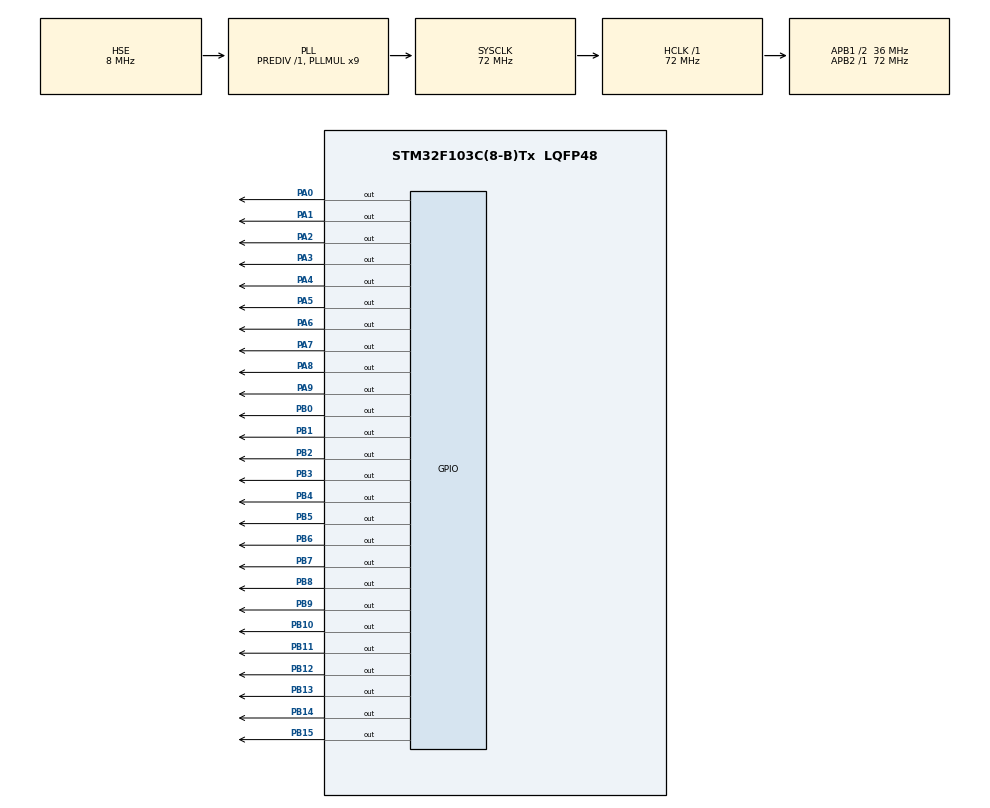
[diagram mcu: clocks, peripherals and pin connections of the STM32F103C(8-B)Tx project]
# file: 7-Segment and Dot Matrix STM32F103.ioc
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FREERTOS.Tasks01=defaultTask,24,128,StartDefaultTask,Default,NULL,Dynamic,NULL,NULL;display,8,256,Dispay01,Default,NULL,Dynamic,NULL,NULL
FREERTOS.configTOTAL_HEAP_SIZE=8096
FREERTOS.configUSE_NEWLIB_REENTRANT=1
Mcu.Family=STM32F1
Mcu.Name=STM32F103C(8-B)Tx
Mcu.Package=LQFP48
NVIC.PriorityGroup=NVIC_PRIORITYGROUP_4
NVIC.TIM3_IRQn=true\:15\:0\:false\:false\:true\:false\:false\:true
NVIC.TimeBase=TIM3_IRQn
NVIC.TimeBaseIP=TIM3
PA0-WKUP.GPIO_PuPd=GPIO_PULLUP
PA0-WKUP.GPIO_Speed=GPIO_SPEED_FREQ_HIGH
PA0-WKUP.PinState=GPIO_PIN_SET
PA0-WKUP.Signal=GPIO_Output
PA1.GPIO_PuPd=GPIO_PULLUP
PA1.GPIO_Speed=GPIO_SPEED_FREQ_HIGH
PA1.PinState=GPIO_PIN_SET
PA1.Signal=GPIO_Output
PA13.Mode=Serial_Wire
PA13.Signal=SYS_JTMS-SWDIO
PA14.Mode=Serial_Wire
PA14.Signal=SYS_JTCK-SWCLK
PA2.GPIO_PuPd=GPIO_PULLUP
PA2.GPIO_Speed=GPIO_SPEED_FREQ_HIGH
PA2.PinState=GPIO_PIN_SET
PA2.Signal=GPIO_Output
PA3.GPIO_PuPd=GPIO_PULLUP
PA3.GPIO_Speed=GPIO_SPEED_FREQ_HIGH
PA3.PinState=GPIO_PIN_SET
PA3.Signal=GPIO_Output
PA4.GPIO_PuPd=GPIO_PULLUP
PA4.GPIO_Speed=GPIO_SPEED_FREQ_HIGH
PA4.PinState=GPIO_PIN_SET
PA4.Signal=GPIO_Output
PA5.GPIO_PuPd=GPIO_PULLUP
PA5.GPIO_Speed=GPIO_SPEED_FREQ_HIGH
PA5.PinState=GPIO_PIN_SET
PA5.Signal=GPIO_Output
PA6.GPIO_PuPd=GPIO_PULLUP
PA6.GPIO_Speed=GPIO_SPEED_FREQ_HIGH
PA6.PinState=GPIO_PIN_SET
PA6.Signal=GPIO_Output
PA7.GPIO_PuPd=GPIO_PULLUP
PA7.GPIO_Speed=GPIO_SPEED_FREQ_HIGH
PA7.PinState=GPIO_PIN_SET
PA7.Signal=GPIO_Output
PA8.GPIO_PuPd=GPIO_PULLUP
PA8.GPIO_Speed=GPIO_SPEED_FREQ_HIGH
PA8.PinState=GPIO_PIN_RESET
PA8.Signal=GPIO_Output
PA9.GPIO_PuPd=GPIO_PULLUP
PA9.GPIO_Speed=GPIO_SPEED_FREQ_HIGH
PA9.PinState=GPIO_PIN_RESET
PA9.Signal=GPIO_Output
PB0.GPIO_ModeDefaultOutputPP=GPIO_MODE_OUTPUT_PP
PB0.GPIO_PuPd=GPIO_PULLUP
PB0.GPIO_Speed=GPIO_SPEED_FREQ_HIGH
PB0.PinState=GPIO_PIN_SET
PB0.Signal=GPIO_Output
PB1.GPIO_ModeDefaultOutputPP=GPIO_MODE_OUTPUT_PP
PB1.GPIO_PuPd=GPIO_PULLUP
PB1.GPIO_Speed=GPIO_SPEED_FREQ_HIGH
PB1.PinState=GPIO_PIN_SET
PB1.Signal=GPIO_Output
PB10.GPIO_ModeDefaultOutputPP=GPIO_MODE_OUTPUT_PP
PB10.GPIO_PuPd=GPIO_PULLUP
PB10.GPIO_Speed=GPIO_SPEED_FREQ_HIGH
PB10.PinState=GPIO_PIN_SET
PB10.Signal=GPIO_Output
PB11.GPIO_ModeDefaultOutputPP=GPIO_MODE_OUTPUT_PP
PB11.GPIO_PuPd=GPIO_PULLUP
PB11.GPIO_Speed=GPIO_SPEED_FREQ_HIGH
PB11.PinState=GPIO_PIN_SET
PB11.Signal=GPIO_Output
PB12.GPIO_ModeDefaultOutputPP=GPIO_MODE_OUTPUT_PP
PB12.GPIO_PuPd=GPIO_PULLUP
PB12.GPIO_Speed=GPIO_SPEED_FREQ_HIGH
PB12.PinState=GPIO_PIN_SET
PB12.Signal=GPIO_Output
PB13.GPIO_ModeDefaultOutputPP=GPIO_MODE_OUTPUT_PP
PB13.GPIO_PuPd=GPIO_PULLUP
PB13.GPIO_Speed=GPIO_SPEED_FREQ_HIGH
PB13.PinState=GPIO_PIN_SET
PB13.Signal=GPIO_Output
PB14.GPIO_ModeDefaultOutputPP=GPIO_MODE_OUTPUT_PP
PB14.GPIO_PuPd=GPIO_PULLUP
PB14.GPIO_Speed=GPIO_SPEED_FREQ_HIGH
PB14.PinState=GPIO_PIN_SET
PB14.Signal=GPIO_Output
PB15.GPIO_ModeDefaultOutputPP=GPIO_MODE_OUTPUT_PP
PB15.GPIO_PuPd=GPIO_PULLUP
PB15.GPIO_Speed=GPIO_SPEED_FREQ_HIGH
PB15.PinState=GPIO_PIN_SET
PB15.Signal=GPIO_Output
PB2.GPIO_ModeDefaultOutputPP=GPIO_MODE_OUTPUT_PP
PB2.GPIO_PuPd=GPIO_PULLDOWN
PB2.GPIO_Speed=GPIO_SPEED_FREQ_HIGH
PB2.PinState=GPIO_PIN_RESET
PB2.Signal=GPIO_Output
PB3.GPIO_ModeDefaultOutputPP=GPIO_MODE_OUTPUT_PP
PB3.GPIO_PuPd=GPIO_PULLDOWN
PB3.GPIO_Speed=GPIO_SPEED_FREQ_HIGH
PB3.PinState=GPIO_PIN_RESET
PB3.Signal=GPIO_Output
PB4.GPIO_ModeDefaultOutputPP=GPIO_MODE_OUTPUT_PP
PB4.GPIO_PuPd=GPIO_PULLDOWN
PB4.GPIO_Speed=GPIO_SPEED_FREQ_HIGH
PB4.PinState=GPIO_PIN_RESET
PB4.Signal=GPIO_Output
PB5.GPIO_ModeDefaultOutputPP=GPIO_MODE_OUTPUT_PP
PB5.GPIO_PuPd=GPIO_PULLDOWN
PB5.GPIO_Speed=GPIO_SPEED_FREQ_HIGH
PB5.PinState=GPIO_PIN_RESET
PB5.Signal=GPIO_Output
PB6.GPIO_ModeDefaultOutputPP=GPIO_MODE_OUTPUT_PP
PB6.GPIO_PuPd=GPIO_PULLDOWN
PB6.GPIO_Speed=GPIO_SPEED_FREQ_HIGH
PB6.PinState=GPIO_PIN_RESET
PB6.Signal=GPIO_Output
PB7.GPIO_ModeDefaultOutputPP=GPIO_MODE_OUTPUT_PP
PB7.GPIO_PuPd=GPIO_PULLDOWN
PB7.GPIO_Speed=GPIO_SPEED_FREQ_HIGH
PB7.PinState=GPIO_PIN_RESET
PB7.Signal=GPIO_Output
PB8.GPIO_ModeDefaultOutputPP=GPIO_MODE_OUTPUT_PP
PB8.GPIO_PuPd=GPIO_PULLDOWN
PB8.GPIO_Speed=GPIO_SPEED_FREQ_HIGH
PB8.PinState=GPIO_PIN_RESET
PB8.Signal=GPIO_Output
PB9.GPIO_ModeDefaultOutputPP=GPIO_MODE_OUTPUT_PP
PB9.GPIO_PuPd=GPIO_PULLDOWN
PB9.GPIO_Speed=GPIO_SPEED_FREQ_HIGH
PB9.PinState=GPIO_PIN_RESET
PB9.Signal=GPIO_Output
PD0-OSC_IN.Mode=HSE-External-Oscillator
PD0-OSC_IN.Signal=RCC_OSC_IN
PD1-OSC_OUT.Mode=HSE-External-Oscillator
PD1-OSC_OUT.Signal=RCC_OSC_OUT
ProjectManager.HeapSize=0x200
ProjectManager.StackSize=0x400
ProjectManager.TargetToolchain=STM32CubeIDE
RCC.AHBFreq_Value=72000000
RCC.APB1CLKDivider=RCC_HCLK_DIV2
RCC.APB1Freq_Value=36000000
RCC.APB1TimFreq_Value=72000000
RCC.APB2Freq_Value=72000000
RCC.APB2TimFreq_Value=72000000
RCC.HCLKFreq_Value=72000000
RCC.PLLMUL=RCC_PLL_MUL9
RCC.PLLSourceVirtual=RCC_PLLSOURCE_HSE
RCC.SYSCLKFreq_VALUE=72000000
RCC.SYSCLKSource=RCC_SYSCLKSOURCE_PLLCLK
RCC.USBFreq_Value=72000000
VP_FREERTOS_VS_CMSIS_V2.Mode=CMSIS_V2
VP_SYS_VS_tim3.Mode=TIM3
board=custom

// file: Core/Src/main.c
/* USER CODE BEGIN Header */
/**
  ******************************************************************************
  * @file           : main.c
  * @brief          : Main program body
  ******************************************************************************
  * @attention
  *
  * Copyright (c) 2022 STMicroelectronics.
  * All rights reserved.
  *
  * This software is licensed under terms that can be found in the LICENSE file
  * in the root directory of this software component.
  * If no LICENSE file comes with this software, it is provided AS-IS.
  *
  ******************************************************************************
  */
/* USER CODE END Header */
#include "main.h"
#include "cmsis_os.h"

/* USER CODE BEGIN Includes */
#include "7_segment_driver.h"
/* USER CODE END Includes */

/* USER CODE BEGIN PTD */
volatile char alpha = 'a';
/* USER CODE END PTD */

/* Definitions for defaultTask */
osThreadId_t defaultTaskHandle;
const osThreadAttr_t defaultTask_attributes = {
  .name = "defaultTask",
  .stack_size = 128 * 4,
  .priority = (osPriority_t) osPriorityNormal,
};
/* Definitions for display */
osThreadId_t displayHandle;
const osThreadAttr_t display_attributes = {
  .name = "display",
  .stack_size = 256 * 4,
  .priority = (osPriority_t) osPriorityLow,
};

void SystemClock_Config(void);
static void MX_GPIO_Init(void);
void StartDefaultTask(void *argument);
void Dispay01(void *argument);

int main(void)
{

  /* MCU Configuration--------------------------------------------------------*/

  /* Reset of all peripherals, Initializes the Flash interface and the Systick. */
  HAL_Init();

  /* Configure the system clock */
  SystemClock_Config();

  /* Initialize all configured peripherals */
  MX_GPIO_Init();
  /* USER CODE BEGIN 2 */
uint16_t counter = 0 , counter_2 = 0;
HAL_GPIO_WritePin(GPIOA, 0x100, GPIO_PIN_SET);

HAL_GPIO_WritePin(GPIOB, 0xFF, GPIO_PIN_RESET);
HAL_GPIO_WritePin(GPIOB, 0xFF00, GPIO_PIN_SET);

  /* USER CODE END 2 */

  /* Init scheduler */
  osKernelInitialize();

  /* Create the thread(s) */
  /* creation of defaultTask */
  defaultTaskHandle = osThreadNew(StartDefaultTask, NULL, &defaultTask_attributes);

  /* creation of display */
  displayHandle = osThreadNew(Dispay01, NULL, &display_attributes);

  /* Start scheduler */
  osKernelStart();

  /* We should never get here as control is now taken by the scheduler */
  /* Infinite loop */
  while (1)
  {

  }
}

void SystemClock_Config(void)
{
  RCC_OscInitTypeDef RCC_OscInitStruct = {0};
  RCC_ClkInitTypeDef RCC_ClkInitStruct = {0};

  /** Initializes the RCC Oscillators according to the specified parameters
  * in the RCC_OscInitTypeDef structure.
  */
  RCC_OscInitStruct.OscillatorType = RCC_OSCILLATORTYPE_HSE;
  RCC_OscInitStruct.HSEState = RCC_HSE_ON;
  RCC_OscInitStruct.HSEPredivValue = RCC_HSE_PREDIV_DIV1;
  RCC_OscInitStruct.HSIState = RCC_HSI_ON;
  RCC_OscInitStruct.PLL.PLLState = RCC_PLL_ON;
  RCC_OscInitStruct.PLL.PLLSource = RCC_PLLSOURCE_HSE;
  RCC_OscInitStruct.PLL.PLLMUL = RCC_PLL_MUL9;
  if (HAL_RCC_OscConfig(&RCC_OscInitStruct) != HAL_OK)
  {
    Error_Handler();
  }
  /** Initializes the CPU, AHB and APB buses clocks
  */
  RCC_ClkInitStruct.ClockType = RCC_CLOCKTYPE_HCLK|RCC_CLOCKTYPE_SYSCLK
                              |RCC_CLOCKTYPE_PCLK1|RCC_CLOCKTYPE_PCLK2;
  RCC_ClkInitStruct.SYSCLKSource = RCC_SYSCLKSOURCE_PLLCLK;
  RCC_ClkInitStruct.AHBCLKDivider = RCC_SYSCLK_DIV1;
  RCC_ClkInitStruct.APB1CLKDivider = RCC_HCLK_DIV2;
  RCC_ClkInitStruct.APB2CLKDivider = RCC_HCLK_DIV1;

  if (HAL_RCC_ClockConfig(&RCC_ClkInitStruct, FLASH_LATENCY_2) != HAL_OK)
  {
    Error_Handler();
  }
}

static void MX_GPIO_Init(void)
{
  GPIO_InitTypeDef GPIO_InitStruct = {0};

  /* GPIO Ports Clock Enable */
  __HAL_RCC_GPIOD_CLK_ENABLE();
  __HAL_RCC_GPIOA_CLK_ENABLE();
  __HAL_RCC_GPIOB_CLK_ENABLE();

  /*Configure GPIO pin Output Level */
  HAL_GPIO_WritePin(GPIOA, GPIO_PIN_0|GPIO_PIN_1|GPIO_PIN_2|GPIO_PIN_3
                          |GPIO_PIN_4|GPIO_PIN_5|GPIO_PIN_6|GPIO_PIN_7, GPIO_PIN_SET);

  /*Configure GPIO pin Output Level */
  HAL_GPIO_WritePin(GPIOB, GPIO_PIN_0|GPIO_PIN_1|GPIO_PIN_10|GPIO_PIN_11
                          |GPIO_PIN_12|GPIO_PIN_13|GPIO_PIN_14|GPIO_PIN_15, GPIO_PIN_SET);

  /*Configure GPIO pin Output Level */
  HAL_GPIO_WritePin(GPIOB, GPIO_PIN_2|GPIO_PIN_3|GPIO_PIN_4|GPIO_PIN_5
                          |GPIO_PIN_6|GPIO_PIN_7|GPIO_PIN_8|GPIO_PIN_9, GPIO_PIN_RESET);

  /*Configure GPIO pin Output Level */
  HAL_GPIO_WritePin(GPIOA, GPIO_PIN_8|GPIO_PIN_9, GPIO_PIN_RESET);

  /*Configure GPIO pins : PA0 PA1 PA2 PA3
                           PA4 PA5 PA6 PA7
                           PA8 PA9 */
  GPIO_InitStruct.Pin = GPIO_PIN_0|GPIO_PIN_1|GPIO_PIN_2|GPIO_PIN_3
                          |GPIO_PIN_4|GPIO_PIN_5|GPIO_PIN_6|GPIO_PIN_7
                          |GPIO_PIN_8|GPIO_PIN_9;
  GPIO_InitStruct.Mode = GPIO_MODE_OUTPUT_PP;
  GPIO_InitStruct.Pull = GPIO_PULLUP;
  GPIO_InitStruct.Speed = GPIO_SPEED_FREQ_HIGH;
  HAL_GPIO_Init(GPIOA, &GPIO_InitStruct);

  /*Configure GPIO pins : PB0 PB1 PB10 PB11
                           PB12 PB13 PB14 PB15 */
  GPIO_InitStruct.Pin = GPIO_PIN_0|GPIO_PIN_1|GPIO_PIN_10|GPIO_PIN_11
                          |GPIO_PIN_12|GPIO_PIN_13|GPIO_PIN_14|GPIO_PIN_15;
  GPIO_InitStruct.Mode = GPIO_MODE_OUTPUT_PP;
  GPIO_InitStruct.Pull = GPIO_PULLUP;
  GPIO_InitStruct.Speed = GPIO_SPEED_FREQ_HIGH;
  HAL_GPIO_Init(GPIOB, &GPIO_InitStruct);

  /*Configure GPIO pins : PB2 PB3 PB4 PB5
                           PB6 PB7 PB8 PB9 */
  GPIO_InitStruct.Pin = GPIO_PIN_2|GPIO_PIN_3|GPIO_PIN_4|GPIO_PIN_5
                          |GPIO_PIN_6|GPIO_PIN_7|GPIO_PIN_8|GPIO_PIN_9;
  GPIO_InitStruct.Mode = GPIO_MODE_OUTPUT_PP;
  GPIO_InitStruct.Pull = GPIO_PULLDOWN;
  GPIO_InitStruct.Speed = GPIO_SPEED_FREQ_HIGH;
  HAL_GPIO_Init(GPIOB, &GPIO_InitStruct);

}

void StartDefaultTask(void *argument)
{
  /* USER CODE BEGIN 5 */
  /* Infinite loop */
  for(;;)
  {
	  alpha ++;
	  if(alpha > 'z')
		  alpha = 'a';

    osDelay(1000);
  }
  /* USER CODE END 5 */
}

void Dispay01(void *argument)
{
  /* USER CODE BEGIN Dispay01 */
  /* Infinite loop */
  for(;;)
  {
	dot_matrix_display_alpha(alpha);
    osDelay(1);
  }
  /* USER CODE END Dispay01 */
}

void HAL_TIM_PeriodElapsedCallback(TIM_HandleTypeDef *htim)
{
  if (htim->Instance == TIM3) {
    HAL_IncTick();
  }
}

void Error_Handler(void)
{
  __disable_irq();
  while (1)
  {
  }
}
